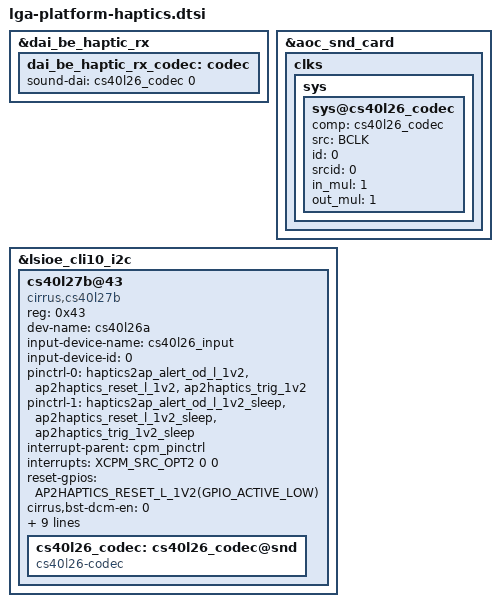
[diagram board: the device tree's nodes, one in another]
// SPDX-License-Identifier: GPL-2.0-only
/*
 * Haptics device tree entries specific to the lga paltform
 *
 * Copyright 2024 Google LLC
 */

#include <dt-bindings/gpio/gpio.h>

&dai_be_haptic_rx {
	dai_be_haptic_rx_codec: codec {
		sound-dai = <&cs40l26_codec 0>;
	};
};

&aoc_snd_card {
	clks {
		sys {
			sys@cs40l26_codec {
				comp = <&cs40l26_codec>;
				src = "BCLK";
				id = <0>;	/* clk id */
				srcid = <0>;	/* clk source */
				in_mul = <1>;	/* in clk multiple */
				out_mul = <1>;	/* out clk multiple */
			};
		};
	};
};

&lsioe_cli10_i2c {
	cs40l27b@43 {
		compatible = "cirrus,cs40l27b";
		reg = <0x43>;
		dev-name = "cs40l26a";			/* sysfs folder name */
		input-device-name = "cs40l26_input";	/* input device name */
		input-device-id = <0>;

		pinctrl-names = "default", "sleep";
		pinctrl-0 = <&haptics2ap_alert_od_l_1v2
			     &ap2haptics_reset_l_1v2
			     &ap2haptics_trig_1v2>;
		pinctrl-1 = <&haptics2ap_alert_od_l_1v2_sleep
			    &ap2haptics_reset_l_1v2_sleep
			    &ap2haptics_trig_1v2_sleep>;

		interrupt-parent = <&cpm_pinctrl>;
		interrupts = <XCPM_SRC_OPT2 0 0>;

		reset-gpios = <AP2HAPTICS_RESET_L_1V2(GPIO_ACTIVE_LOW)>;

		cirrus,bst-dcm-en = <0>;
		cirrus,pwle-zero-cross-en;
		cirrus,vpbr-enable;
		cirrus,vpbr-thld-uv = <3008000>;	/* 3.008V */
		cirrus,bst-expl-mode-disable;
		cirrus,bst-ipk-microamp = <2500000>;	/* 2.5A */
		cirrus,bst-ctl-microvolt = <11000000>;	/* 11V */
		cirrus,f0-default = <0x208000>;		/* 130 Hz * 0x4000 */
		cirrus,redc-default = <0x68000>;	/* 13 Ohm */
		cirrus,pm-active-timeout-ms = <5>;

		status = "okay";

		cs40l26_codec: cs40l26_codec@snd {
			#sound-dai-cells = <1>;
			compatible = "cs40l26-codec";
			status = "okay";
		};
	};
};
